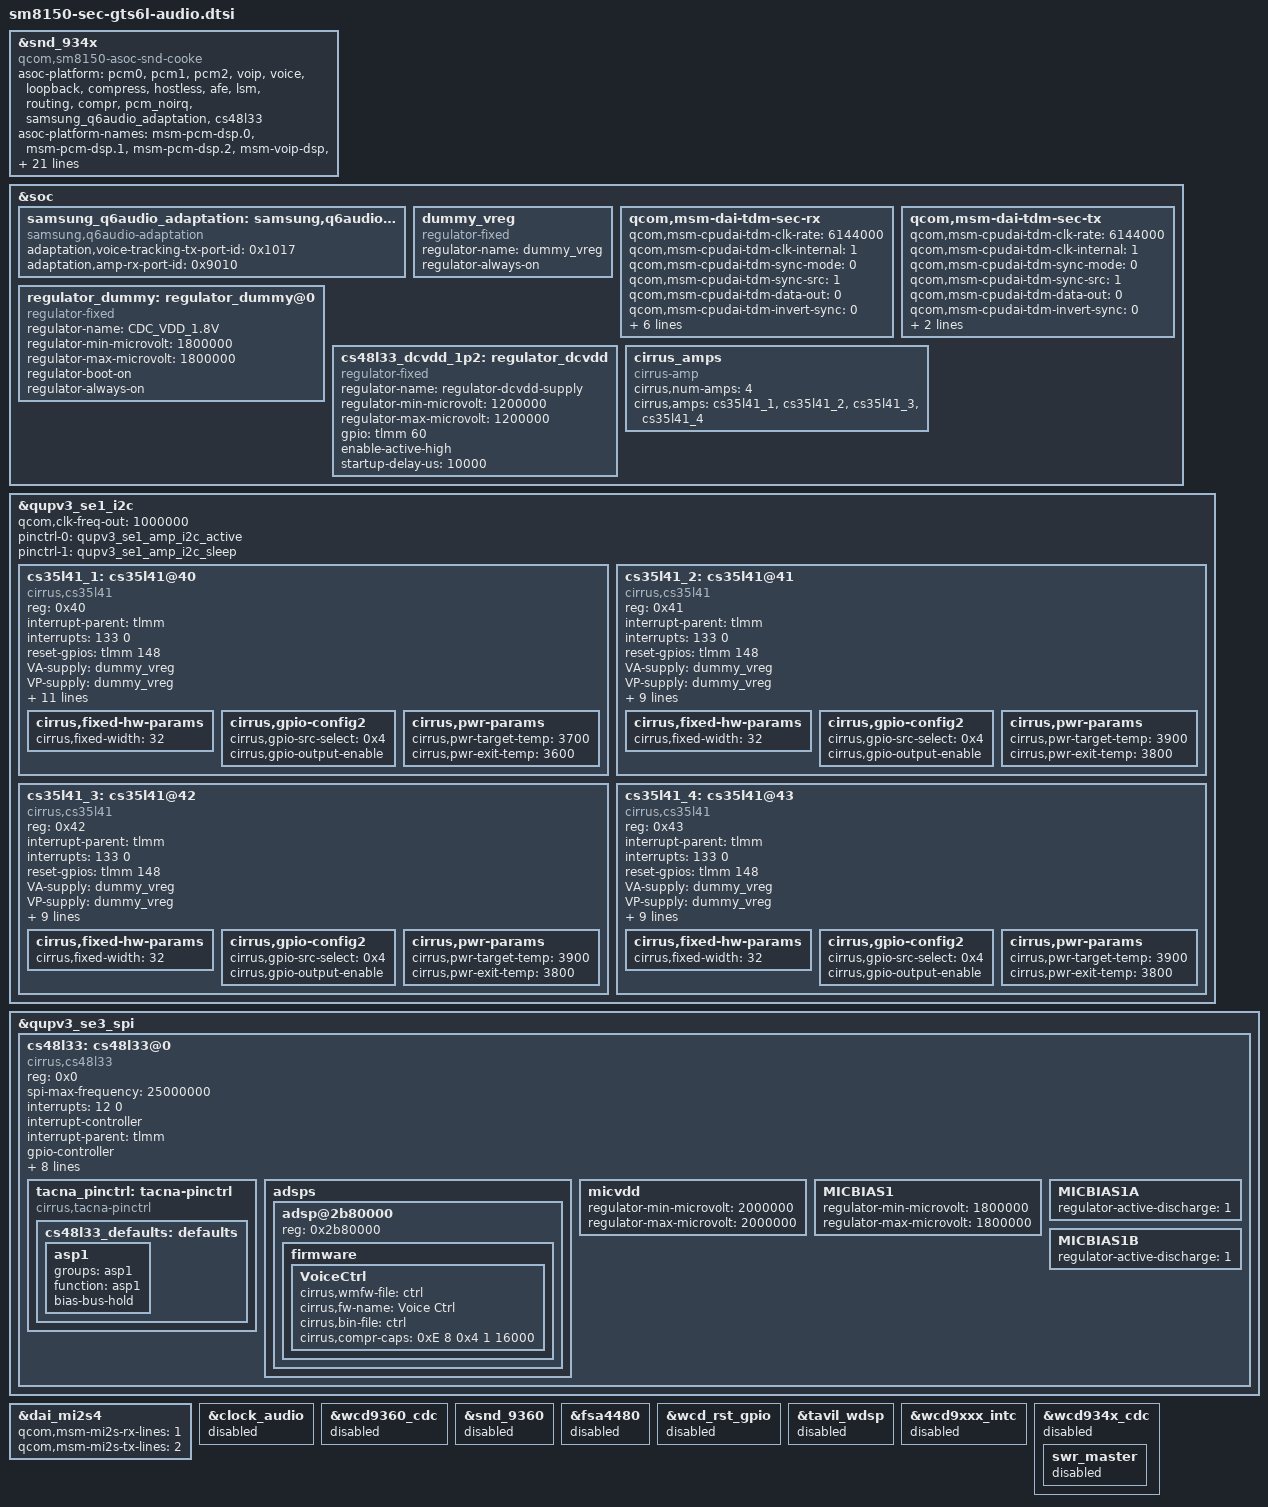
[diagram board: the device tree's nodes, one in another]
/* Copyright (c) 2016-2017, The Linux Foundation. All rights reserved.
 *
 * This program is free software; you can redistribute it and/or modify
 * it under the terms of the GNU General Public License version 2 and
 * only version 2 as published by the Free Software Foundation.
 *
 * This program is distributed in the hope that it will be useful,
 * but WITHOUT ANY WARRANTY; without even the implied warranty of
 * MERCHANTABILITY or FITNESS FOR A PARTICULAR PURPOSE.  See the
 * GNU General Public License for more details.
 */

#include "../qcom/sm8150-audio-overlay.dtsi"

&snd_934x {
	compatible = "qcom,sm8150-asoc-snd-cooke";

	asoc-platform = <&pcm0>, <&pcm1>, <&pcm2>, <&voip>, <&voice>,
			<&loopback>, <&compress>, <&hostless>,
			<&afe>, <&lsm>, <&routing>, <&compr>,
			<&pcm_noirq>, <&samsung_q6audio_adaptation>,
			<&cs48l33>;
	asoc-platform-names = "msm-pcm-dsp.0", "msm-pcm-dsp.1",
			"msm-pcm-dsp.2", "msm-voip-dsp",
			"msm-pcm-voice", "msm-pcm-loopback",
			"msm-compress-dsp", "msm-pcm-hostless",
			"msm-pcm-afe", "msm-lsm-client",
			"msm-pcm-routing", "msm-compr-dsp",
			"msm-pcm-dsp-noirq", "q6audio-adaptation",
			"cs48l32-codec";
	qcom,audio-routing =
		"SYSCLK", "FLL1",
		"RR SPK", "RR AMP SPK",
		"RL SPK", "RL AMP SPK",
		"FR SPK", "FR AMP SPK",
		"FL SPK", "FL AMP SPK";

	qcom,wcn-btfm = <1>;
	qcom,wsa-max-devs = <0>;
	qcom,hph-en1-gpio = <0>;
	qcom,hph-en0-gpio = <0>;
	fsa4480-i2c-handle = <0>;
	pinctrl-names = "quin_mi2s_enable", "quin_mi2s_disable";
	pinctrl-0 = <&quin_mi2s_active &quin_mi2s_sd0_active
					&quin_mi2s_sd1_active>;
	pinctrl-1 = <&quin_mi2s_sleep &quin_mi2s_sd0_sleep
					&quin_mi2s_sd1_sleep>;

	cirrus,sysclk = <1 4 98304000>;
	cirrus,fll1-refclk = <1 0 32768 49152000>;
	cirrus,fll1-refclk-bclk = <1 8 0 49152000>;
};

&soc {
	samsung_q6audio_adaptation: samsung,q6audio-adaptation {
		compatible = "samsung,q6audio-adaptation";
		adaptation,voice-tracking-tx-port-id = <0x1017>;
		adaptation,amp-rx-port-id = <0x9010>;
	};

	dummy_vreg: dummy_vreg {
		compatible = "regulator-fixed";
		status = "ok";
		regulator-name = "dummy_vreg";
		regulator-always-on;
	};

	qcom,msm-dai-tdm-sec-rx {
		qcom,msm-cpudai-tdm-clk-rate = <6144000>;
		qcom,msm-cpudai-tdm-clk-internal = <1>;
		qcom,msm-cpudai-tdm-sync-mode = <0>;
		qcom,msm-cpudai-tdm-sync-src = <1>;
		qcom,msm-cpudai-tdm-data-out = <0>;
		qcom,msm-cpudai-tdm-invert-sync = <0>;
		qcom,msm-cpudai-tdm-data-delay = <1>;
		qcom,msm-cpudai-tdm-clk-attribute = /bits/ 16 <1>;

		pinctrl-names = "default", "sleep";
		pinctrl-0 = <&sec_tdm_active &sec_tdm_din_active
				&sec_tdm_dout_active>;
		pinctrl-1 = <&sec_tdm_sleep &sec_tdm_din_sleep
				&sec_tdm_dout_sleep>;
	};

	qcom,msm-dai-tdm-sec-tx {
		qcom,msm-cpudai-tdm-clk-rate = <6144000>;
		qcom,msm-cpudai-tdm-clk-internal = <1>;
		qcom,msm-cpudai-tdm-sync-mode = <0>;
		qcom,msm-cpudai-tdm-sync-src = <1>;
		qcom,msm-cpudai-tdm-data-out = <0>;
		qcom,msm-cpudai-tdm-invert-sync = <0>;
		qcom,msm-cpudai-tdm-data-delay = <1>;		
		qcom,msm-cpudai-tdm-clk-attribute = /bits/ 16 <1>;
	};

	regulator_dummy: regulator_dummy@0 {
		compatible = "regulator-fixed";

		regulator-name = "CDC_VDD_1.8V";
		regulator-min-microvolt = <1800000>;
		regulator-max-microvolt = <1800000>;
		regulator-boot-on;
		regulator-always-on;
	};

	cs48l33_dcvdd_1p2: regulator_dcvdd {
		compatible = "regulator-fixed";
		regulator-name = "regulator-dcvdd-supply";
		status = "ok";
		regulator-min-microvolt = <1200000>;
		regulator-max-microvolt = <1200000>;
		gpio = <&tlmm 60 0>; /* VOICE_LDO_ENABLE */
		enable-active-high;
		startup-delay-us = <10000>;
	};

	cirrus_amps {
		compatible = "cirrus-amp";
		cirrus,num-amps = <4>;
		cirrus,amps = <&cs35l41_1 &cs35l41_2 &cs35l41_3 &cs35l41_4>;
	};
};

&qupv3_se1_i2c {
	qcom,clk-freq-out = <1000000>;
	status = "ok";
	pinctrl-0 = <&qupv3_se1_amp_i2c_active>;
	pinctrl-1 = <&qupv3_se1_amp_i2c_sleep>;

	cs35l41_1: cs35l41@40 {
		#sound-dai-cells = <1>;
		compatible = "cirrus,cs35l41";
		reg = <0x40>;
		interrupt-parent = <&tlmm>;
		interrupts = <133 0>;
		reset-gpios = <&tlmm 148 0>;
		VA-supply = <&dummy_vreg>;
		VP-supply = <&dummy_vreg>;
		cirrus,asp-sdout-hiz = <0x3>;

		cirrus,mfd-suffix = "_r";

		cirrus,dsp-noise-gate-enable;
		cirrus,dsp-noise-gate-delay = <0x2>;
		cirrus,dsp-noise-gate-threshold = <0x6>;

		cirrus,hw-noise-gate-select = <0x3F>;
		cirrus,hw-noise-gate-delay = <0x2>;
		cirrus,hw-noise-gate-threshold = <0x6>;
		cirrus,boost-peak-milliamp = <4100>;

		pinctrl-names = "default";
  		pinctrl-0 = <&cs35l41_int_active &cs35l41_rst_default>;

		cirrus,fixed-hw-params	{
			cirrus,fixed-width = <32>;
		};

		cirrus,gpio-config2 {
			cirrus,gpio-src-select = <0x4>;
			cirrus,gpio-output-enable;
		};

		cirrus,pwr-params {
			cirrus,pwr-target-temp = <3700>;
			cirrus,pwr-exit-temp = <3600>;
		};
	};

	cs35l41_2: cs35l41@41 {
		#sound-dai-cells = <1>;
		compatible = "cirrus,cs35l41";
		reg = <0x41>;
		interrupt-parent = <&tlmm>;
		interrupts = <133 0>;
		reset-gpios = <&tlmm 148 0>;
		VA-supply = <&dummy_vreg>;
		VP-supply = <&dummy_vreg>;
		cirrus,asp-sdout-hiz = <0x3>;

		cirrus,mfd-suffix = "";

		cirrus,dsp-noise-gate-enable;
		cirrus,dsp-noise-gate-delay = <0x2>;
		cirrus,dsp-noise-gate-threshold = <0x6>;

		cirrus,hw-noise-gate-select = <0x3F>;
		cirrus,hw-noise-gate-delay = <0x2>;
		cirrus,hw-noise-gate-threshold = <0x6>;
		cirrus,boost-peak-milliamp = <4100>;

		cirrus,fixed-hw-params	{
			cirrus,fixed-width = <32>;
		};

		cirrus,gpio-config2 {
			cirrus,gpio-src-select = <0x4>;
			cirrus,gpio-output-enable;
		};

		cirrus,pwr-params {
			cirrus,pwr-target-temp = <3900>;
			cirrus,pwr-exit-temp = <3800>;
		};
		};

	cs35l41_3: cs35l41@42 {
		#sound-dai-cells = <1>;
		compatible = "cirrus,cs35l41";
		reg = <0x42>;
		interrupt-parent = <&tlmm>;
		interrupts = <133 0>;
		reset-gpios = <&tlmm 148 0>;
		VA-supply = <&dummy_vreg>;
		VP-supply = <&dummy_vreg>;
		cirrus,asp-sdout-hiz = <0x3>;

		cirrus,mfd-suffix = "_br";

		cirrus,dsp-noise-gate-enable;
		cirrus,dsp-noise-gate-delay = <0x2>;
		cirrus,dsp-noise-gate-threshold = <0x6>;

		cirrus,hw-noise-gate-select = <0x3F>;
		cirrus,hw-noise-gate-delay = <0x2>;
		cirrus,hw-noise-gate-threshold = <0x6>;
		cirrus,boost-peak-milliamp = <4100>;

		cirrus,fixed-hw-params	{
			cirrus,fixed-width = <32>;
		};

		cirrus,gpio-config2 {
			cirrus,gpio-src-select = <0x4>;
			cirrus,gpio-output-enable;
		};
	
		cirrus,pwr-params {
			cirrus,pwr-target-temp = <3900>;
			cirrus,pwr-exit-temp = <3800>;
		};
	};

	cs35l41_4: cs35l41@43 {
		#sound-dai-cells = <1>;
		compatible = "cirrus,cs35l41";
		reg = <0x43>;
		interrupt-parent = <&tlmm>;
		interrupts = <133 0>;
		reset-gpios = <&tlmm 148 0>;
		VA-supply = <&dummy_vreg>;
		VP-supply = <&dummy_vreg>;
		cirrus,asp-sdout-hiz = <0x3>;

		cirrus,mfd-suffix = "_b";

		cirrus,dsp-noise-gate-enable;
		cirrus,dsp-noise-gate-delay = <0x2>;
		cirrus,dsp-noise-gate-threshold = <0x6>;

		cirrus,hw-noise-gate-select = <0x3F>;
		cirrus,hw-noise-gate-delay = <0x2>;
		cirrus,hw-noise-gate-threshold = <0x6>;
		cirrus,boost-peak-milliamp = <4100>;

		cirrus,fixed-hw-params	{
			cirrus,fixed-width = <32>;
		};

		cirrus,gpio-config2 {
			cirrus,gpio-src-select = <0x4>;
			cirrus,gpio-output-enable;
		};

		cirrus,pwr-params {
			cirrus,pwr-target-temp = <3900>;
			cirrus,pwr-exit-temp = <3800>;
		};
	};
};

&qupv3_se3_spi {
	status = "okay";

	cs48l33: cs48l33@0 {
		compatible = "cirrus,cs48l33";
		reg = <0x0>;

		spi-max-frequency = <25000000>;

		interrupts = <12 0>;
		interrupt-controller;
		#interrupt-cells = <2>;
		interrupt-parent = <&tlmm>;
		gpio-controller;
		#gpio-cells = <2>;
		#sound-dai-cells = <1>;

		VDD_A-supply = <&regulator_dummy>;
		VDD_IO1-supply = <&regulator_dummy>;
		VDD1_CP-supply = <&regulator_dummy>;
		VDD_D-supply = <&cs48l33_dcvdd_1p2>;

		reset-gpios = <&pm8150l_gpios 2 0>;

		cirrus,in-type = <
			0 0 0 0 /* IN1 */
		>;

		pinctrl-names = "active";
		pinctrl-0 = <&cs48l33_defaults &cs48l33_int_default &cs48l33_rst_default>;

		tacna_pinctrl: tacna-pinctrl {
			compatible = "cirrus,tacna-pinctrl";

			cs48l33_defaults: defaults {
				asp1 {
					groups = "asp1";
					function = "asp1";
					bias-bus-hold;
				};
			};
		};

		adsps {
			#address-cells = <1>;
			#size-cells = <0>;

			adsp@2b80000 {
				reg = <0x2b80000>;
				firmware {
					VoiceCtrl {
						cirrus,wmfw-file = "ctrl";
						cirrus,fw-name = "Voice Ctrl";
						cirrus,bin-file = "ctrl";
						cirrus,compr-caps = <0xE 8 0x4 1 16000>;
					};
				};
			};
		};

		micvdd {
			regulator-min-microvolt = <2000000>;
			regulator-max-microvolt = <2000000>;
		};

		MICBIAS1 {
			regulator-min-microvolt = <1800000>;
			regulator-max-microvolt = <1800000>;
		};

		MICBIAS1A {
			regulator-active-discharge = <1>;
		};

		MICBIAS1B {
			regulator-active-discharge = <1>;
		};
	};
};

&dai_mi2s4 {
	qcom,msm-mi2s-rx-lines = <1>;
	qcom,msm-mi2s-tx-lines = <2>;
};

&clock_audio {
	status = "disabled";
};

&wcd9360_cdc {
	status = "disabled";
};

&snd_9360 {
	status = "disabled";
};

&fsa4480 {
	status = "disabled";
};

&wcd_rst_gpio {
	status = "disabled";
};

&tavil_wdsp {
	status = "disabled";
};

&wcd9xxx_intc {
	status = "disabled";
};

&wcd934x_cdc {
	status = "disabled";
	swr_master {
		status = "disabled";
	};
};
